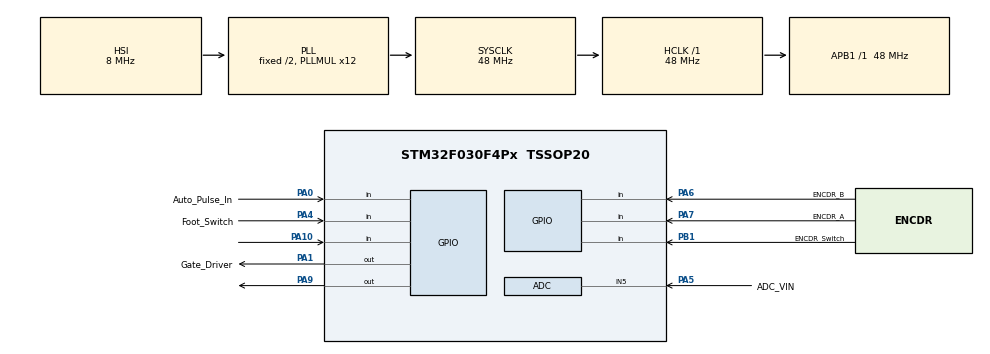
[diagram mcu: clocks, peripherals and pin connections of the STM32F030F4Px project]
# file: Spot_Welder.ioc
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ADC.ContinuousConvMode=ENABLE
ADC.Resolution=ADC_RESOLUTION_10B
ADC.SamplingTime=ADC_SAMPLETIME_55CYCLES_5
Mcu.Family=STM32F0
Mcu.Name=STM32F030F4Px
Mcu.Package=TSSOP20
PA0.GPIO_Label=Auto_Pulse_In
PA0.Signal=GPIO_Input
PA1.GPIO_Label=Gate_Driver
PA1.GPIO_Speed=GPIO_SPEED_FREQ_HIGH
PA1.Signal=GPIO_Output
PA10.Signal=GPIO_Input
PA13.Mode=Serial_Wire
PA13.Signal=SYS_SWDIO
PA14.Mode=Serial_Wire
PA14.Signal=SYS_SWCLK
PA4.GPIO_Label=Foot_Switch
PA4.Signal=GPIO_Input
PA5.GPIO_Label=ADC_VIN
PA5.Mode=IN5
PA5.Signal=ADC_IN5
PA6.GPIO_Label=ENCDR_B
PA6.Signal=GPIO_Input
PA7.GPIO_Label=ENCDR_A
PA7.Signal=GPIO_Input
PA9.GPIO_FMA9=__NULL
PA9.GPIO_Speed=GPIO_SPEED_FREQ_LOW
PA9.Signal=GPIO_Output
PB1.GPIO_Label=ENCDR_Switch
PB1.Signal=GPIO_Input
ProjectManager.HeapSize=0x200
ProjectManager.StackSize=0x400
ProjectManager.TargetToolchain=STM32CubeIDE
RCC.AHBFreq_Value=48000000
RCC.APB1Freq_Value=48000000
RCC.APB1TimFreq_Value=48000000
RCC.HCLKFreq_Value=48000000
RCC.PLLMUL=RCC_PLL_MUL12
RCC.SYSCLKFreq_VALUE=48000000
RCC.SYSCLKSource=RCC_SYSCLKSOURCE_PLLCLK
board=custom

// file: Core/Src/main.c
/* USER CODE BEGIN Header */
/**
  ******************************************************************************
  * @file           : main.c
  * @brief          : Main program body
  ******************************************************************************
  * @attention
  *
  * <h2><center>&copy; Copyright (c) 2019 STMicroelectronics.
  * All rights reserved.</center></h2>
  *
  * This software component is licensed by ST under BSD 3-Clause license,
  * the "License"; You may not use this file except in compliance with the
  * License. You may obtain a copy of the License at:
  *                        opensource.org/licenses/BSD-3-Clause
  *
  ******************************************************************************
  */
/* USER CODE END Header */

#include "main.h"
#include "adc.h"
#include "gpio.h"

void SystemClock_Config(void);
/* USER CODE BEGIN PFP */
#include "spot_welder_main.h"
/* USER CODE END PFP */

int main(void)
{

  /* MCU Configuration--------------------------------------------------------*/

  /* Reset of all peripherals, Initializes the Flash interface and the Systick. */
  HAL_Init();

  /* Configure the system clock */
  SystemClock_Config();

  /* Initialize all configured peripherals */
  MX_GPIO_Init();
  MX_ADC_Init();
  /* USER CODE BEGIN 2 */
  HAL_ADC_Start(&hadc);
  Spot_Welder_Main();

  /* USER CODE END 2 */

  /* Infinite loop */
  while (1)
  {

  }
}

void SystemClock_Config(void)
{
  RCC_OscInitTypeDef RCC_OscInitStruct = {0};
  RCC_ClkInitTypeDef RCC_ClkInitStruct = {0};

  /** Initializes the CPU, AHB and APB busses clocks
  */
  RCC_OscInitStruct.OscillatorType = RCC_OSCILLATORTYPE_HSI|RCC_OSCILLATORTYPE_HSI14;
  RCC_OscInitStruct.HSIState = RCC_HSI_ON;
  RCC_OscInitStruct.HSI14State = RCC_HSI14_ON;
  RCC_OscInitStruct.HSICalibrationValue = RCC_HSICALIBRATION_DEFAULT;
  RCC_OscInitStruct.HSI14CalibrationValue = 16;
  RCC_OscInitStruct.PLL.PLLState = RCC_PLL_ON;
  RCC_OscInitStruct.PLL.PLLSource = RCC_PLLSOURCE_HSI;
  RCC_OscInitStruct.PLL.PLLMUL = RCC_PLL_MUL12;
  RCC_OscInitStruct.PLL.PREDIV = RCC_PREDIV_DIV1;
  if (HAL_RCC_OscConfig(&RCC_OscInitStruct) != HAL_OK)
  {
    Error_Handler();
  }
  /** Initializes the CPU, AHB and APB busses clocks
  */
  RCC_ClkInitStruct.ClockType = RCC_CLOCKTYPE_HCLK|RCC_CLOCKTYPE_SYSCLK
                              |RCC_CLOCKTYPE_PCLK1;
  RCC_ClkInitStruct.SYSCLKSource = RCC_SYSCLKSOURCE_PLLCLK;
  RCC_ClkInitStruct.AHBCLKDivider = RCC_SYSCLK_DIV1;
  RCC_ClkInitStruct.APB1CLKDivider = RCC_HCLK_DIV1;

  if (HAL_RCC_ClockConfig(&RCC_ClkInitStruct, FLASH_LATENCY_1) != HAL_OK)
  {
    Error_Handler();
  }
}

void Error_Handler(void)
{
}

/************************ (C) COPYRIGHT STMicroelectronics *****END OF FILE****/
